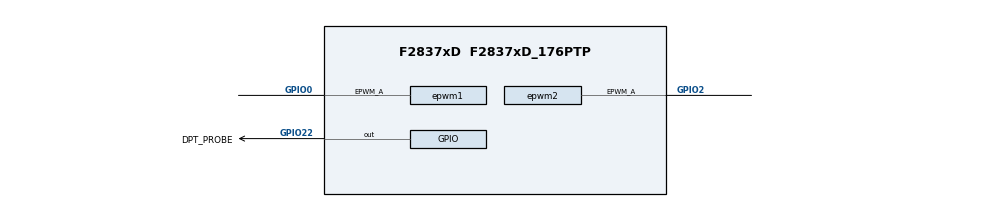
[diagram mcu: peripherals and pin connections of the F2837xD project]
/**
 *
 * @cliArgs --device "F2837xD" --part "F2837xD_176PTP" --package "F2837xD_176PTP" --context "CPU1" --product "C2000WARE@26.01.00.00"
 * @versions {"tool":"1.28.0+4696"}
 */

/**
 * Import the modules used in this configuration.
 */
const epwm  = scripting.addModule("/driverlib/epwm.js", {}, false);
const epwm1 = epwm.addInstance();
const epwm2 = epwm.addInstance();
const gpio  = scripting.addModule("/driverlib/gpio.js", {}, false);
const gpio1 = gpio.addInstance();

/**
 * Write custom configuration values to the imported modules.
 */
const default_warning = scripting.addModule("/driverlib/default_warning.js", {}, false);
scripting.suppress("Add the \'Device Support\' module in order to use Clock Tree tool and generate device support files\\. This suggestion can be ignored if not using the Clock Tree tool\\.", default_warning);

epwm1.$name                            = "myEPWM1";
epwm1.epwmEventTrigger_enableInterrupt = true;
epwm1.epwmEventTrigger_interruptSource = "EPWM_INT_TBCTR_PERIOD";
epwm1.useCase                          = "CUSTOM";
epwm1.useInterfacePins                 = ["EPWM#A"];
epwm1.epwm.$assign                     = "EPWM1";
epwm1.epwm.epwm_aPin.$assign           = "GPIO0";

epwm2.$name                  = "myEPWM2";
epwm2.useCase                = "CUSTOM";
epwm2.useInterfacePins       = ["EPWM#A"];
epwm2.epwm.$assign           = "EPWM2";
epwm2.epwm.epwm_aPin.$assign = "GPIO2";

gpio1.direction       = "GPIO_DIR_MODE_OUT";
gpio1.$name           = "DPT_PROBE";
gpio1.gpioPin.$assign = "GPIO22";
